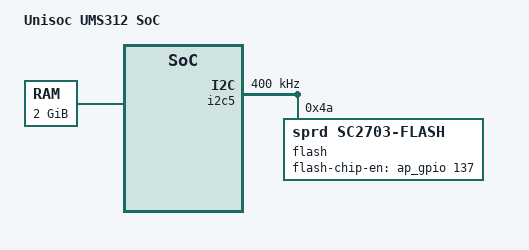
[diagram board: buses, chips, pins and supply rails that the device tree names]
// SPDX-License-Identifier: (GPL-2.0+ OR MIT)
/*
 * Unisoc Sharkl5 platform DTS file
 *
 * Copyright (C) 2018, Unisoc Communications Inc.
 */

/dts-v1/;

#include <dt-bindings/input/input.h>
#include <dt-bindings/gpio/gpio.h>
#include <dt-bindings/mfd/sprd,sc2730-regs.h>
#include <dt-bindings/mfd/sprd,sc2730-mask.h>

#include "ums312.dtsi"
#include "sprd-sound-fe-be.dtsi"
#include "sc2730.dtsi"
#include "ums312-go-common.dtsi"

/ {
	model = "Unisoc UMS312 SoC";

	compatible = "sprd,ums312";

	sprd,sc-id = "ums312 1000 1000";

	memory: memory {
		device_type = "memory";
		reg = <0x80000000 0x80000000>;
	};
};

&i2c5 {
	status = "okay";
	clock-frequency = <400000>;

	flash: sc2703-flash@4a {
		compatible = "sprd,sc2703-flash";
		reg = <0x4a>;
		flash-chip-en-gpios = <&ap_gpio 137 0>;
	};
};


